# GD32F5HC register map
File version: 1.0
CPU: CM33 r0p4, little endian, MPU, FPU, 4 interrupt priority bits
Registers are 32-bit, read-write, reset 0x0 unless marked. A register's access mark holds for its fields unless they carry their own. Offsets are from the block's base; [hi:lo] are bit positions; {n}, {i} and the like mark numbered series.

## RCU — Reset and clock unit
Base 0x40023800
Same registers: SEC_RCU 0x50023800
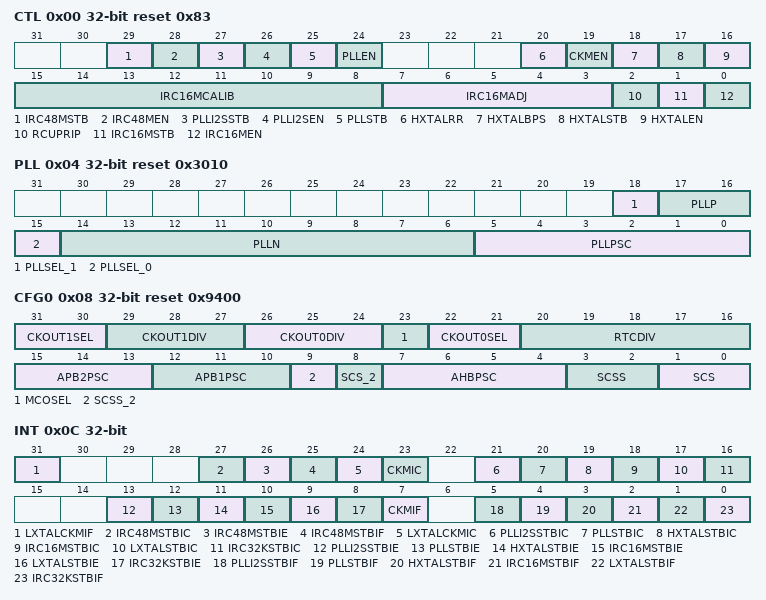
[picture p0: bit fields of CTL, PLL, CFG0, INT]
0x00 CTL access per field reset 0x83 — Control register
  [29] IRC48MSTB ro — IRC48M oscillator stabilization flag
  [28] IRC48MEN rw — Internal high speed oscillator enable
  [27] PLLI2SSTB ro — PLLI2S clock stabilization flag
  [26] PLLI2SEN rw — PLLI2S enable
  [25] PLLSTB ro — PLL clock stabilization flag
  [24] PLLEN rw — PLL enable
  [20] HXTALRR rw — HXTAL ready reset signal
  [19] CKMEN rw — HXTAL clock monitor enable
  [18] HXTALBPS rw — High speed crystal oscillator (HXTAL) clock bypass mode enable
  [17] HXTALSTB ro — High speed crystal oscillator (HXTAL) clock stabilization flag
  [16] HXTALEN rw — High speed crystal oscillator (HXTAL) enable
  [15:8] IRC16MCALIB ro — Internal 16MHz RC oscillator calibration value register
  [7:3] IRC16MADJ rw — Internal 16MHz RC oscillator clock trim adjust value
  [2] RCUPRIP rw — RCU privilege protection
  [1] IRC16MSTB ro — IRC16M Internal 16MHz RC Oscillator stabilization flag
  [0] IRC16MEN rw — Internal 16MHz RC oscillator enable
0x04 PLL reset 0x3010
  [18] PLLSEL_1 — Configure clock source selection together with PLLSEL_0
  [17:16] PLLP — The PLLP output frequency division factor from PLL VCO clock
  [15] PLLSEL_0 — PLL (PLLsys and PLLI2S) clock source selection
  [14:6] PLLN — The PLL VCO clock multiplication factor
  [5:0] PLLPSC — The PLL VCO source clock prescaler
0x08 CFG0 access per field reset 0x9400 — Clock configuration register 0
  [31:30] CKOUT1SEL rw — CKOUT1 clock source selection
  [29:27] CKOUT1DIV rw — The CK_OUT1 divider which the CK_OUT1 frequency can be reduced
  [26:24] CKOUT0DIV rw — The CK_OUT0 divider which the CK_OUT0 frequency can be reduced
  [23] MCOSEL rw — CKOUT0/CKOUT1 clock source High-precision clock
  [22:21] CKOUT0SEL rw — CKOUT0 clock source selection
  [20:16] RTCDIV rw — RTC clock divider factor
  [15:13] APB2PSC rw — APB2 prescaler selection
  [12:10] APB1PSC rw — APB1 prescaler selection
  [9] SCSS_2 ro — System clock switch status
  [8] SCS_2 rw — System clock switch
  [7:4] AHBPSC rw — AHB prescaler selection
  [3:2] SCSS ro — System clock switch status
  [1:0] SCS rw — System clock switch
0x0C INT access per field — Clock interrupt register
  [31] LXTALCKMIF ro — LXTAL clock stuck interrupt flag
  [27] IRC48MSTBIC wo — IRC48M stabilization interrupt clear
  [26] IRC48MSTBIE rw — IRC48M Stabilization interrupt enable
  [25] IRC48MSTBIF ro — IRC48M stabilization interrupt flag
  [24] LXTALCKMIC rw — LXTAL clock stuck interrupt clear
  [23] CKMIC wo — HXTAL clock stuck interrupt clear
  [21] PLLI2SSTBIC wo — PLLI2S stabilization interrupt clear
  [20] PLLSTBIC wo — PLL stabilization interrupt clear
  [19] HXTALSTBIC wo — HXTAL stabilization interrupt clear
  [18] IRC16MSTBIC wo — IRC16M stabilization interrupt clear
  [17] LXTALSTBIC wo — LXTAL stabilization interrupt clear
  [16] IRC32KSTBIC wo — IRC32K Stabilization interrupt clear
  [13] PLLI2SSTBIE rw — PLLI2S Stabilization interrupt enable
  [12] PLLSTBIE rw — PLL Stabilization interrupt enable
  [11] HXTALSTBIE rw — HXTAL Stabilization interrupt enable
  [10] IRC16MSTBIE rw — IRC16M Stabilization interrupt enable
  [9] LXTALSTBIE rw — LXTAL Stabilization interrupt enable
  [8] IRC32KSTBIE rw — IRC32K Stabilization interrupt enable
  [7] CKMIF ro — HXTAL Clock Stuck Interrupt Flag
  [5] PLLI2SSTBIF ro — PLLI2S stabilization interrupt flag
  [4] PLLSTBIF ro — PLL stabilization interrupt flag
  [3] HXTALSTBIF ro — HXTAL stabilization interrupt flag
  [2] IRC16MSTBIF ro — IRC16M stabilization interrupt flag
  [1] LXTALSTBIF ro — LXTAL stabilization interrupt flag
  [0] IRC32KSTBIF ro — IRC32K stabilization interrupt flag
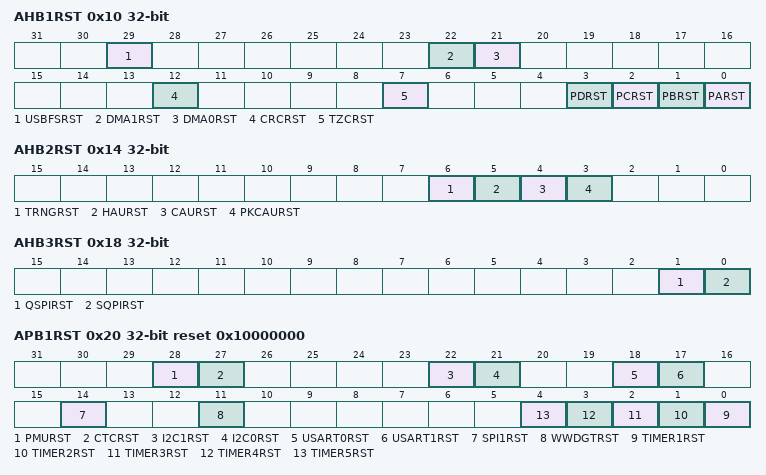
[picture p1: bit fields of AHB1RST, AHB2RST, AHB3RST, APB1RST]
0x10 AHB1RST — AHB1 reset register
  [29] USBFSRST — USBFS reset
  [22] DMA1RST — DMA1 reset
  [21] DMA0RST — DMA0 reset
  [12] CRCRST — CRC reset
  [7] TZCRST — GTZC reset
  [3] PDRST — GPIO port D reset
  [2] PCRST — GPIO port C reset
  [1] PBRST — GPIO port B reset
  [0] PARST — GPIO port A reset
0x14 AHB2RST — AHB2 reset register
  [6] TRNGRST — TRNG reset
  [5] HAURST — HAU reset
  [4] CAURST — CAU reset
  [3] PKCAURST — PKCAU reset
0x18 AHB3RST — AHB3 reset register
  [1] QSPIRST — QSPI reset
  [0] SQPIRST — SQPI reset
0x20 APB1RST reset 0x10000000 — APB1 reset register
  [28] PMURST — PMU reset
  [27] CTCRST — CTC reset
  [22] I2C1RST — I2C1 reset
  [21] I2C0RST — I2C0 reset
  [18] USART0RST — USART0 reset
  [17] USART1RST — USART1 reset
  [14] SPI1RST — SPI1 reset
  [11] WWDGTRST — WWDGT reset
  [n-1] TIMER{n}RST (n=1..5) — TIMER{n} reset
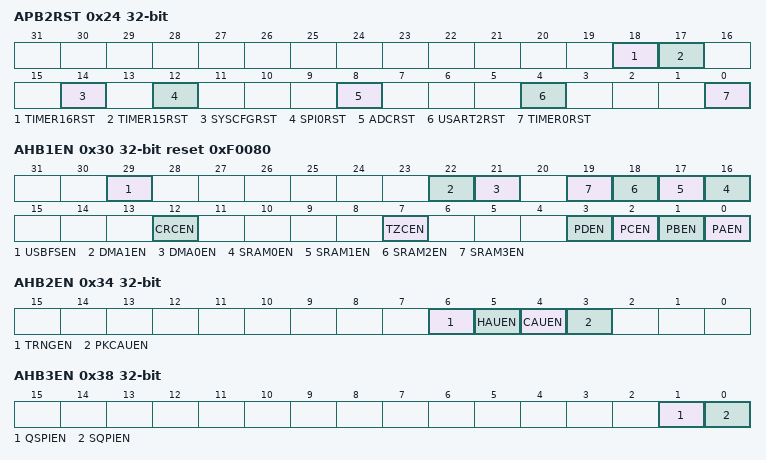
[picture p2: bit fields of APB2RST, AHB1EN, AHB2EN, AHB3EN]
0x24 APB2RST — APB2 reset register
  [18] TIMER16RST — TIMER16 reset
  [17] TIMER15RST — TIMER15 reset
  [14] SYSCFGRST — SYSCFG reset
  [12] SPI0RST — SPI0 reset
  [8] ADCRST — ADC reset
  [4] USART2RST — USART2 reset
  [0] TIMER0RST — TIMER0 reset
0x30 AHB1EN reset 0xF0080 — AHB1 enable register
  [29] USBFSEN — USBFS clock enable
  [22] DMA1EN — DMA1 clock enable
  [21] DMA0EN — DMA0 clock enable
  [n+16] SRAM{n}EN (n=0..3) — SRAM{n} clock enable
  [12] CRCEN — CRC clock enable
  [7] TZCEN — GTZC clock enable
  [3] PDEN — GPIO port D clock enable
  [2] PCEN — GPIO port C clock enable
  [1] PBEN — GPIO port B clock enable
  [0] PAEN — GPIO port A clock enable
0x34 AHB2EN — AHB2 enable register
  [6] TRNGEN — TRNG clock enable
  [5] HAUEN — HAU clock enable
  [4] CAUEN — CAU clock enable
  [3] PKCAUEN — PKCAU clock enable
0x38 AHB3EN — AHB3 enable register
  [1] QSPIEN — QSPI clock enable
  [0] SQPIEN — SQPI clock enable
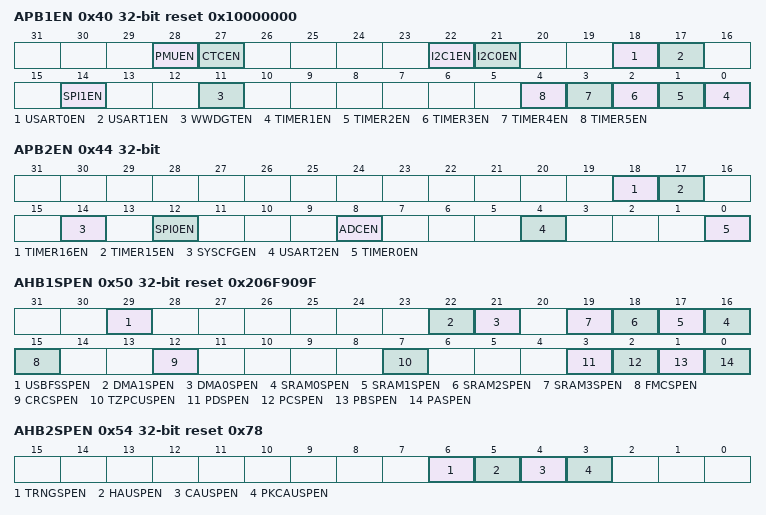
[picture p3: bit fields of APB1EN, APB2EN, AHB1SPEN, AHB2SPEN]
0x40 APB1EN reset 0x10000000 — APB1 enable register
  [28] PMUEN — PMU clock enable
  [27] CTCEN — PMU clock enable
  [22] I2C1EN — I2C1 clock enable
  [21] I2C0EN — I2C0 clock enable
  [18] USART0EN — USART0 clock enable
  [17] USART1EN — USART1 clock enable
  [14] SPI1EN — SPI1 clock enable
  [11] WWDGTEN — WWDGT clock enable
  [n-1] TIMER{n}EN (n=1..5) — TIMER{n} clock enable
0x44 APB2EN — APB2 enable register
  [18] TIMER16EN — TIMER16 clock enable
  [17] TIMER15EN — TIMER15 clock enable
  [14] SYSCFGEN — SYSCFG clock enable
  [12] SPI0EN — SPI0 clock enable
  [8] ADCEN — ADC clock enable
  [4] USART2EN — USART2 clock enable
  [0] TIMER0EN — TIMER0 clock enable
0x50 AHB1SPEN reset 0x206F909F — AHB1 sleep mode enable register
  [29] USBFSSPEN — USBFS clock enable when sleep mode
  [22] DMA1SPEN — DMA1 clock enable when sleep mode
  [21] DMA0SPEN — DMA0 clock enable when sleep mode
  [n+16] SRAM{n}SPEN (n=0..3) — SRAM{n} clock enable when sleep mode
  [15] FMCSPEN — FMC clock enable when sleep mode
  [12] CRCSPEN — CRC clock enable when sleep mode
  [7] TZPCUSPEN — TZPCU clock enable when sleep mode
  [3] PDSPEN — GPIO port D clock enable when sleep mode
  [2] PCSPEN — GPIO port C clock enable when sleep mode
  [1] PBSPEN — GPIO port B clock enable when sleep mode
  [0] PASPEN — GPIO port A clock enable when sleep mode
0x54 AHB2SPEN reset 0x78 — AHB2 sleep mode enable register
  [6] TRNGSPEN — TRNG clock enable when sleep mode
  [5] HAUSPEN — HAU clock enable when sleep mode
  [4] CAUSPEN — CAU clock enable when sleep mode
  [3] PKCAUSPEN — PKCAU clock enable when sleep mode
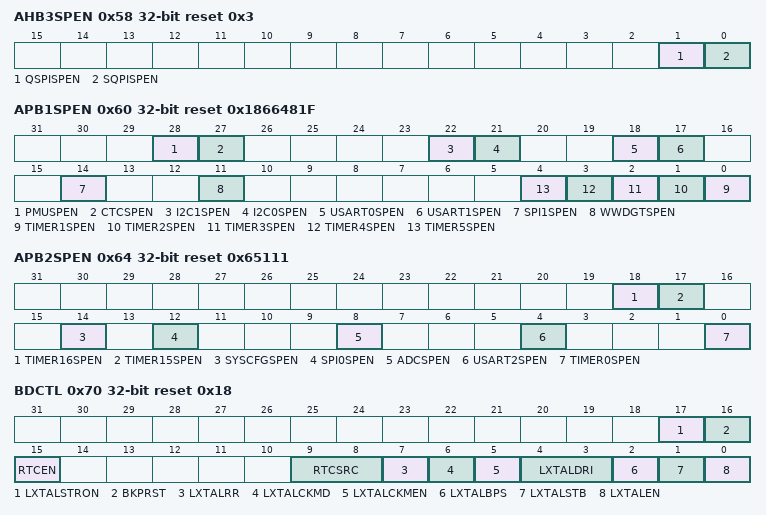
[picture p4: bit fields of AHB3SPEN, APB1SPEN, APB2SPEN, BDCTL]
0x58 AHB3SPEN reset 0x3 — AHB3 sleep mode enable register
  [1] QSPISPEN — QSPI clock enable when sleep mode
  [0] SQPISPEN — SQPI clock enable when sleep mode
0x60 APB1SPEN reset 0x1866481F — APB1 sleep mode enable register
  [28] PMUSPEN — PMU clock enable when sleep mode
  [27] CTCSPEN — CTC clock enable when sleep mode
  [22] I2C1SPEN — I2C1 clock enable when sleep mode
  [21] I2C0SPEN — I2C0 clock enable when sleep mode
  [18] USART0SPEN — USART0 clock enable when sleep mode
  [17] USART1SPEN — USART1 clock enable when sleep mode
  [14] SPI1SPEN — SPI1 clock enable when sleep mode
  [11] WWDGTSPEN — WWDGT clock enable when sleep mode
  [n-1] TIMER{n}SPEN (n=1..5) — TIMER{n} clock enable when sleep mode
0x64 APB2SPEN reset 0x65111 — APB2 sleep mode enable register
  [18] TIMER16SPEN — TIMER16 clock enable when sleep mode
  [17] TIMER15SPEN — TIMER15 clock enable when sleep mode
  [14] SYSCFGSPEN — SYSCFG clock enable when sleep mode
  [12] SPI0SPEN — SPI0 clock enable when sleep mode
  [8] ADCSPEN — ADC clock enable when sleep mode
  [4] USART2SPEN — USART2 clock enable when sleep mode
  [0] TIMER0SPEN — TIMER0 clock enable when sleep mode
0x70 BDCTL access per field reset 0x18 — Backup domain control register
  [17] LXTALSTRON rw — LXTAL start circuit open off control
  [16] BKPRST rw — Backup domain reset
  [15] RTCEN rw — RTC clock enable
  [9:8] RTCSRC rw — RTC clock entry selection
  [7] LXTALRR rw — LXTAL ready reset signal
  [6] LXTALCKMD rw — LXTAL clock failure Detection
  [5] LXTALCKMEN rw — LXTAL clock monitor enable
  [4:3] LXTALDRI rw — LXTAL drive capability
  [2] LXTALBPS rw — LXTAL bypass mode enable
  [1] LXTALSTB ro — Low speed crystal oscillator stabilization flag
  [0] LXTALEN rw — LXTAL enable
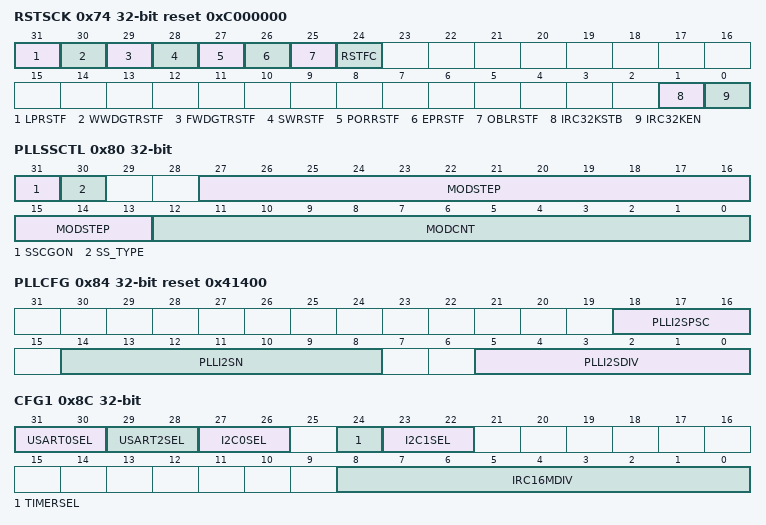
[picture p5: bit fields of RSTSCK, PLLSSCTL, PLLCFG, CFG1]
0x74 RSTSCK access per field reset 0xC000000 — Reset source/clock register
  [31] LPRSTF ro — Low-power reset flag
  [30] WWDGTRSTF ro — Window watchdog timer reset flag
  [29] FWDGTRSTF ro — Free watchdog timer reset flag
  [28] SWRSTF ro — Software reset flag
  [27] PORRSTF ro — Power reset flag
  [26] EPRSTF ro — External pin reset flag
  [25] OBLRSTF ro — Option byte loader reset flag
  [24] RSTFC rw — Reset flag clear
  [1] IRC32KSTB ro — IRC32K stabilization flag
  [0] IRC32KEN rw — IRC32K enable
0x80 PLLSSCTL — PLL clock spread spectrum control register
  [31] SSCGON — PLL spread spectrum modulation enable
  [30] SS_TYPE — PLL spread spectrum modulation type select
  [27:13] MODSTEP — These bits configure PLL spread spectrum modulation profile amplitude and frequency
  [12:0] MODCNT — These bits configure PLL spread spectrum modulation profile amplitude and frequency
0x84 PLLCFG reset 0x41400 — PLL clock configuration register
  [18:16] PLLI2SPSC — The PLLI2S VCO source clock pre-scale.
  [14:8] PLLI2SN — The PLLI2S VCO clock multiplication factor
  [5:0] PLLI2SDIV — PLLI2S clock divider factor.
0x8C CFG1 — Clock configuration register 1
  [31:30] USART0SEL — USART0 clock source selection
  [29:28] USART2SEL — USART2 clock source selection
  [27:26] I2C0SEL — I2C0 clock source selection
  [24] TIMERSEL — TIMER clock selection
  [23:22] I2C1SEL — I2C1Clock Source Selection
  [8:0] IRC16MDIV — IRC16M clock divider factor for system clock.
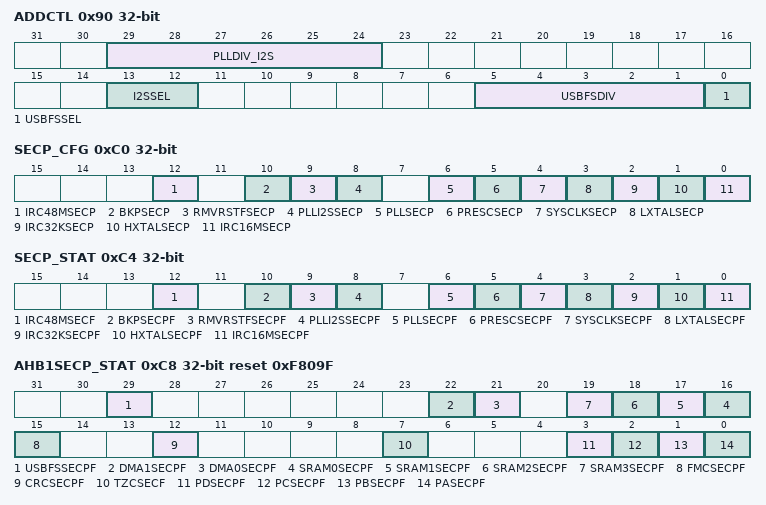
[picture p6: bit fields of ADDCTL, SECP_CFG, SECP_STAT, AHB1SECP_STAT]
0x90 ADDCTL — Additional clock control register
  [29:24] PLLDIV_I2S — The PLL divider factor for I2S clock
  [13:12] I2SSEL — I2S Clock Source Selection
  [5:1] USBFSDIV — USBFS clock divider factor
  [0] USBFSSEL — USBFS clock selection
0xC0 SECP_CFG — Secure protection configuration register
  [12] IRC48MSECP — IRC48M security
  [10] BKPSECP — BKP security protection
  [9] RMVRSTFSECP — Remove reset flag security protection
  [8] PLLI2SSECP — PLLI2S configuration and status bits security protection
  [6] PLLSECP — Main PLL configuration and status bits security protection
  [5] PRESCSECP — AHBx/APBx prescaler configuration bits security protection
  [4] SYSCLKSECP — SYSCLK clock selection, clock output on MCO configuration
  [3] LXTALSECP — LXTAL clock configuration and status bits security protection
  [2] IRC32KSECP — IRC32K clock configuration and status bits security protection
  [1] HXTALSECP — HXTAL clock configuration and status bits security protection
  [0] IRC16MSECP — IRC16M clock configuration and status bits security protection
0xC4 SECP_STAT ro — Secure protection status register
  [12] IRC48MSECF — IRC48M security flag
  [10] BKPSECPF — BKP security protection flag
  [9] RMVRSTFSECPF — Remove reset flag security protection flag
  [8] PLLI2SSECPF — PLLI2S configuration and status bits security protection flag
  [6] PLLSECPF — Main PLL configuration and status bits security protection flag
  [5] PRESCSECPF — AHBx / APBx prescaler configuration bits security protection flag
  [4] SYSCLKSECPF — SYSCLK clock selection, clock output on MCO configuration
  [3] LXTALSECPF — LXTAL clock configuration and status bits security protection flag
  [2] IRC32KSECPF — IRC32K clock configuration and status bits security protection flag
  [1] HXTALSECPF — HXTAL clock configuration and status bits security protection flag
  [0] IRC16MSECPF — IRC16M clock configuration and status bits security protection flag
0xC8 AHB1SECP_STAT ro reset 0xF809F — AHB1 secure protection status register
  [29] USBFSSECPF — USBFS security protection flag
  [22] DMA1SECPF — DMA1 security protection flag
  [21] DMA0SECPF — DMA0 security protection flag
  [n+16] SRAM{n}SECPF (n=0..3) — SRAM{n} security protection flag
  [15] FMCSECPF — FMC security protection flag
  [12] CRCSECPF — CRC security protection flag
  [7] TZCSECF — TZPCU security flag
  [3] PDSECPF — GPIO port D security flag
  [2] PCSECPF — GPIO port C security protection flag
  [1] PBSECPF — GPIO port B security protection flag
  [0] PASECPF — GPIO port A security protection flag
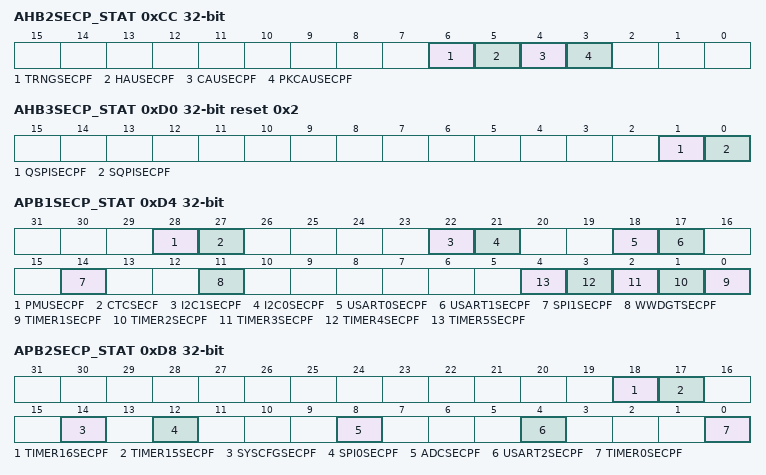
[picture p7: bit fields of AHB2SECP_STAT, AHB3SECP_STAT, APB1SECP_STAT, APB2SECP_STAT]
0xCC AHB2SECP_STAT — AHB2 secure protection status register
  [6] TRNGSECPF — TRNG security protection flag
  [5] HAUSECPF — HAU security protection flag
  [4] CAUSECPF — CAU security protection flag
  [3] PKCAUSECPF — PKCAU security protection flag
0xD0 AHB3SECP_STAT ro reset 0x2 — AHB3 secure protection status register
  [1] QSPISECPF — QSPI security protection flag
  [0] SQPISECPF — SQPI security protection flag
0xD4 APB1SECP_STAT ro — APB1 secure protection status register
  [28] PMUSECPF — PMU security protection flag
  [27] CTCSECF — CTC security flag
  [22] I2C1SECPF — I2C1 security protection flag
  [21] I2C0SECPF — I2C0 security protection flag
  [18] USART0SECPF — USART0 security protection flag
  [17] USART1SECPF — USART1 security protection flag
  [14] SPI1SECPF — SPI1 security protection flag
  [11] WWDGTSECPF — WWDGT security protection flag
  [n-1] TIMER{n}SECPF (n=1..5) — TIMER{n} security protection flag
0xD8 APB2SECP_STAT ro — APB2 secure protection status register
  [18] TIMER16SECPF — TIMER16 security protection flag
  [17] TIMER15SECPF — TIMER15 security protection flag
  [14] SYSCFGSECPF — SYSCFG security protection flag
  [12] SPI0SECPF — SPI0 security protection flag
  [8] ADCSECPF — ADC security protection flag
  [4] USART2SECPF — USART2 security protection flag
  [0] TIMER0SECPF — TIMER0 security protection flag
